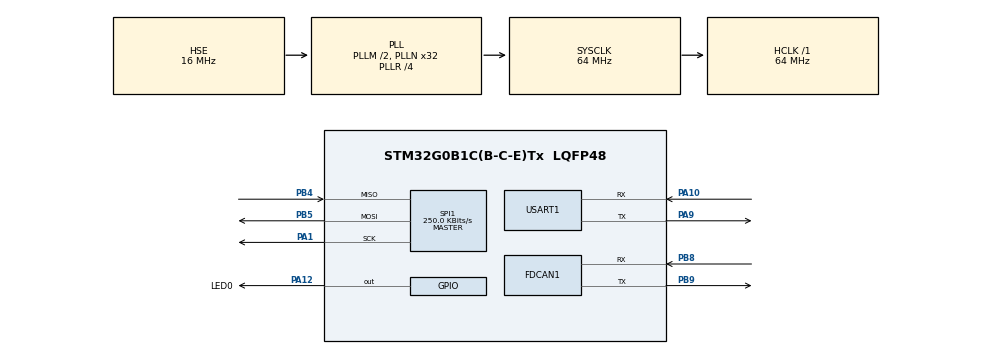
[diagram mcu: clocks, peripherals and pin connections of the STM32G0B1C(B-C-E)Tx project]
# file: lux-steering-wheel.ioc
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FDCAN1.CalculateBaudRateNominal=500000
FDCAN1.CalculateTimeBitNominal=2000
FDCAN1.CalculateTimeQuantumNominal=125.0
FDCAN1.DataPrescaler=8
FDCAN1.DataTimeSeg1=13
FDCAN1.DataTimeSeg2=2
FDCAN1.ExtFiltersNbr=8
FDCAN1.NominalPrescaler=8
FDCAN1.NominalTimeSeg1=12
FDCAN1.NominalTimeSeg2=3
FDCAN1.StdFiltersNbr=28
Mcu.Family=STM32G0
Mcu.Name=STM32G0B1C(B-C-E)Tx
Mcu.Package=LQFP48
NVIC.TIM14_IRQn=true\:0\:0\:false\:false\:true\:true\:true\:true
NVIC.TIM16_FDCAN_IT0_IRQn=true\:0\:0\:false\:false\:true\:true\:true\:true
NVIC.TIM17_FDCAN_IT1_IRQn=true\:0\:0\:false\:false\:true\:true\:true\:true
NVIC.TIM3_TIM4_IRQn=true\:0\:0\:false\:false\:true\:true\:true\:true
NVIC.TIM6_DAC_LPTIM1_IRQn=true\:0\:0\:false\:false\:false\:true\:true\:true
NVIC.TIM7_LPTIM2_IRQn=true\:0\:0\:false\:false\:true\:true\:true\:true
NVIC.USART1_IRQn=true\:0\:0\:false\:false\:true\:true\:true\:true
PA1.Mode=Full_Duplex_Master
PA1.Signal=SPI1_SCK
PA10.Mode=Asynchronous
PA10.Signal=USART1_RX
PA12\ [PA10].GPIO_Label=LED0
PA12\ [PA10].Signal=GPIO_Output
PA13.Mode=Serial_Wire
PA13.Signal=SYS_SWDIO
PA14-BOOT0.Mode=Serial_Wire
PA14-BOOT0.Signal=SYS_SWCLK
PA9.Mode=Asynchronous
PA9.Signal=USART1_TX
PB4.Mode=Full_Duplex_Master
PB4.Signal=SPI1_MISO
PB5.Mode=Full_Duplex_Master
PB5.Signal=SPI1_MOSI
PB8.Mode=FDCAN_Activate
PB8.Signal=FDCAN1_RX
PB9.Mode=FDCAN_Activate
PB9.Signal=FDCAN1_TX
PF0-OSC_IN\ (PF0).Mode=HSE-External-Oscillator
PF0-OSC_IN\ (PF0).Signal=RCC_OSC_IN
PF1-OSC_OUT\ (PF1).Mode=HSE-External-Oscillator
PF1-OSC_OUT\ (PF1).Signal=RCC_OSC_OUT
ProjectManager.HeapSize=0x200
ProjectManager.StackSize=0x400
ProjectManager.TargetToolchain=STM32CubeIDE
RCC.ADCFreq_Value=64000000
RCC.AHBFreq_Value=64000000
RCC.CortexFreq_Value=64000000
RCC.EXTERNAL_CLOCK_VALUE=48000
RCC.HCLKFreq_Value=64000000
RCC.HSE_VALUE=16000000
RCC.HSI48_VALUE=48000000
RCC.HSI_VALUE=16000000
RCC.LSE_VALUE=32768
RCC.PLLM=RCC_PLLM_DIV2
RCC.PLLN=32
RCC.PLLQ=RCC_PLLQ_DIV4
RCC.PLLR=RCC_PLLR_DIV4
RCC.PLLSourceVirtual=RCC_PLLSOURCE_HSE
RCC.SYSCLKFreq_VALUE=64000000
RCC.SYSCLKSource=RCC_SYSCLKSOURCE_PLLCLK
RCC.USBFreq_Value=48000000
RCC.VCOOutputFreq_Value=256000000
SPI1.BaudRatePrescaler=SPI_BAUDRATEPRESCALER_256
SPI1.CalculateBaudRate=250.0 KBits/s
SPI1.DataSize=SPI_DATASIZE_8BIT
SPI1.Direction=SPI_DIRECTION_2LINES
SPI1.Mode=SPI_MODE_MASTER
SPI1.VirtualNSS=VM_NSSHARD
SPI1.VirtualType=VM_MASTER
TIM14.AutoReloadPreload=TIM_AUTORELOAD_PRELOAD_ENABLE
TIM14.Period=(1000/20)-1
TIM14.Prescaler=64000-1
TIM16.AutoReloadPreload=TIM_AUTORELOAD_PRELOAD_ENABLE
TIM16.Period=100-1
TIM16.Prescaler=64000-1
TIM17.AutoReloadPreload=TIM_AUTORELOAD_PRELOAD_ENABLE
TIM17.Period=2000-1
TIM17.Prescaler=64000-1
TIM2.Prescaler=63
TIM4.Prescaler=79
TIM6.AutoReloadPreload=TIM_AUTORELOAD_PRELOAD_ENABLE
TIM6.Period=10-1
TIM6.Prescaler=64000-1
TIM7.AutoReloadPreload=TIM_AUTORELOAD_PRELOAD_ENABLE
TIM7.Period=100-1
TIM7.Prescaler=64000-1
USART1.OverSampling=UART_OVERSAMPLING_16
USART1.VirtualMode-Asynchronous=VM_ASYNC
VP_SYS_VS_DBSignals.Mode=DisableDeadBatterySignals
VP_TIM14_VS_ClockSourceINT.Mode=Enable_Timer
VP_TIM16_VS_ClockSourceINT.Mode=Enable_Timer
VP_TIM17_VS_ClockSourceINT.Mode=Enable_Timer
VP_TIM2_VS_ClockSourceINT.Mode=Internal
VP_TIM4_VS_ClockSourceINT.Mode=Internal
VP_TIM6_VS_ClockSourceINT.Mode=Enable_Timer
VP_TIM7_VS_ClockSourceINT.Mode=Enable_Timer
board=custom

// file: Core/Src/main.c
/* USER CODE BEGIN Header */
/**
  ******************************************************************************
  * @file           : main.c
  * @brief          : Main program body
  ******************************************************************************
  * @attention
  *
  * Copyright (c) 2025 STMicroelectronics.
  * All rights reserved.
  *
  * This software is licensed under terms that can be found in the LICENSE file
  * in the root directory of this software component.
  * If no LICENSE file comes with this software, it is provided AS-IS.
  *
  ******************************************************************************
  */
/* USER CODE END Header */
#include "main.h"

/* USER CODE BEGIN Includes */
#include "run.h"
/* USER CODE END Includes */

FDCAN_HandleTypeDef hfdcan1;

SPI_HandleTypeDef hspi1;

TIM_HandleTypeDef htim2;
TIM_HandleTypeDef htim4;
TIM_HandleTypeDef htim6;
TIM_HandleTypeDef htim7;
TIM_HandleTypeDef htim14;
TIM_HandleTypeDef htim16;
TIM_HandleTypeDef htim17;

UART_HandleTypeDef huart1;

void SystemClock_Config(void);
static void MX_GPIO_Init(void);
static void MX_FDCAN1_Init(void);
static void MX_USART1_UART_Init(void);
static void MX_TIM6_Init(void);
static void MX_TIM7_Init(void);
static void MX_TIM16_Init(void);
static void MX_TIM17_Init(void);
static void MX_TIM14_Init(void);
static void MX_SPI1_Init(void);
static void MX_TIM4_Init(void);
static void MX_TIM2_Init(void);

int main(void)
{

  /* MCU Configuration--------------------------------------------------------*/

  /* Reset of all peripherals, Initializes the Flash interface and the Systick. */
  HAL_Init();

  /* Configure the system clock */
  SystemClock_Config();

  /* Initialize all configured peripherals */
  MX_GPIO_Init();
  MX_FDCAN1_Init();
  MX_USART1_UART_Init();
  MX_TIM6_Init();
  MX_TIM7_Init();
  MX_TIM16_Init();
  MX_TIM17_Init();
  MX_TIM14_Init();
  MX_SPI1_Init();
  MX_TIM4_Init();
  MX_TIM2_Init();
  run();
  /* Infinite loop */
  while (1)
  {

  }
}

void SystemClock_Config(void)
{
  RCC_OscInitTypeDef RCC_OscInitStruct = {0};
  RCC_ClkInitTypeDef RCC_ClkInitStruct = {0};

  /** Configure the main internal regulator output voltage
  */
  HAL_PWREx_ControlVoltageScaling(PWR_REGULATOR_VOLTAGE_SCALE1);

  /** Initializes the RCC Oscillators according to the specified parameters
  * in the RCC_OscInitTypeDef structure.
  */
  RCC_OscInitStruct.OscillatorType = RCC_OSCILLATORTYPE_HSE;
  RCC_OscInitStruct.HSEState = RCC_HSE_ON;
  RCC_OscInitStruct.PLL.PLLState = RCC_PLL_ON;
  RCC_OscInitStruct.PLL.PLLSource = RCC_PLLSOURCE_HSE;
  RCC_OscInitStruct.PLL.PLLM = RCC_PLLM_DIV2;
  RCC_OscInitStruct.PLL.PLLN = 32;
  RCC_OscInitStruct.PLL.PLLP = RCC_PLLP_DIV2;
  RCC_OscInitStruct.PLL.PLLQ = RCC_PLLQ_DIV4;
  RCC_OscInitStruct.PLL.PLLR = RCC_PLLR_DIV4;
  if (HAL_RCC_OscConfig(&RCC_OscInitStruct) != HAL_OK)
  {
    Error_Handler();
  }

  /** Initializes the CPU, AHB and APB buses clocks
  */
  RCC_ClkInitStruct.ClockType = RCC_CLOCKTYPE_HCLK|RCC_CLOCKTYPE_SYSCLK
                              |RCC_CLOCKTYPE_PCLK1;
  RCC_ClkInitStruct.SYSCLKSource = RCC_SYSCLKSOURCE_PLLCLK;
  RCC_ClkInitStruct.AHBCLKDivider = RCC_SYSCLK_DIV1;
  RCC_ClkInitStruct.APB1CLKDivider = RCC_HCLK_DIV1;

  if (HAL_RCC_ClockConfig(&RCC_ClkInitStruct, FLASH_LATENCY_2) != HAL_OK)
  {
    Error_Handler();
  }
}

static void MX_FDCAN1_Init(void)
{

  hfdcan1.Instance = FDCAN1;
  hfdcan1.Init.ClockDivider = FDCAN_CLOCK_DIV1;
  hfdcan1.Init.FrameFormat = FDCAN_FRAME_CLASSIC;
  hfdcan1.Init.Mode = FDCAN_MODE_NORMAL;
  hfdcan1.Init.AutoRetransmission = DISABLE;
  hfdcan1.Init.TransmitPause = DISABLE;
  hfdcan1.Init.ProtocolException = DISABLE;
  hfdcan1.Init.NominalPrescaler = 8;
  hfdcan1.Init.NominalSyncJumpWidth = 1;
  hfdcan1.Init.NominalTimeSeg1 = 12;
  hfdcan1.Init.NominalTimeSeg2 = 3;
  hfdcan1.Init.DataPrescaler = 8;
  hfdcan1.Init.DataSyncJumpWidth = 1;
  hfdcan1.Init.DataTimeSeg1 = 13;
  hfdcan1.Init.DataTimeSeg2 = 2;
  hfdcan1.Init.StdFiltersNbr = 28;
  hfdcan1.Init.ExtFiltersNbr = 8;
  hfdcan1.Init.TxFifoQueueMode = FDCAN_TX_FIFO_OPERATION;
  if (HAL_FDCAN_Init(&hfdcan1) != HAL_OK)
  {
    Error_Handler();
  }

}

static void MX_SPI1_Init(void)
{

  /* SPI1 parameter configuration*/
  hspi1.Instance = SPI1;
  hspi1.Init.Mode = SPI_MODE_MASTER;
  hspi1.Init.Direction = SPI_DIRECTION_2LINES;
  hspi1.Init.DataSize = SPI_DATASIZE_8BIT;
  hspi1.Init.CLKPolarity = SPI_POLARITY_LOW;
  hspi1.Init.CLKPhase = SPI_PHASE_1EDGE;
  hspi1.Init.NSS = SPI_NSS_SOFT;
  hspi1.Init.BaudRatePrescaler = SPI_BAUDRATEPRESCALER_256;
  hspi1.Init.FirstBit = SPI_FIRSTBIT_MSB;
  hspi1.Init.TIMode = SPI_TIMODE_DISABLE;
  hspi1.Init.CRCCalculation = SPI_CRCCALCULATION_DISABLE;
  hspi1.Init.CRCPolynomial = 7;
  hspi1.Init.CRCLength = SPI_CRC_LENGTH_DATASIZE;
  hspi1.Init.NSSPMode = SPI_NSS_PULSE_ENABLE;
  if (HAL_SPI_Init(&hspi1) != HAL_OK)
  {
    Error_Handler();
  }

}

static void MX_TIM2_Init(void)
{

  TIM_ClockConfigTypeDef sClockSourceConfig = {0};
  TIM_MasterConfigTypeDef sMasterConfig = {0};

  htim2.Instance = TIM2;
  htim2.Init.Prescaler = 63;
  htim2.Init.CounterMode = TIM_COUNTERMODE_UP;
  htim2.Init.Period = 4294967295;
  htim2.Init.ClockDivision = TIM_CLOCKDIVISION_DIV1;
  htim2.Init.AutoReloadPreload = TIM_AUTORELOAD_PRELOAD_DISABLE;
  if (HAL_TIM_Base_Init(&htim2) != HAL_OK)
  {
    Error_Handler();
  }
  sClockSourceConfig.ClockSource = TIM_CLOCKSOURCE_INTERNAL;
  if (HAL_TIM_ConfigClockSource(&htim2, &sClockSourceConfig) != HAL_OK)
  {
    Error_Handler();
  }
  sMasterConfig.MasterOutputTrigger = TIM_TRGO_RESET;
  sMasterConfig.MasterSlaveMode = TIM_MASTERSLAVEMODE_DISABLE;
  if (HAL_TIMEx_MasterConfigSynchronization(&htim2, &sMasterConfig) != HAL_OK)
  {
    Error_Handler();
  }

}

static void MX_TIM4_Init(void)
{

  TIM_ClockConfigTypeDef sClockSourceConfig = {0};
  TIM_MasterConfigTypeDef sMasterConfig = {0};

  htim4.Instance = TIM4;
  htim4.Init.Prescaler = 79;
  htim4.Init.CounterMode = TIM_COUNTERMODE_UP;
  htim4.Init.Period = 65535;
  htim4.Init.ClockDivision = TIM_CLOCKDIVISION_DIV1;
  htim4.Init.AutoReloadPreload = TIM_AUTORELOAD_PRELOAD_DISABLE;
  if (HAL_TIM_Base_Init(&htim4) != HAL_OK)
  {
    Error_Handler();
  }
  sClockSourceConfig.ClockSource = TIM_CLOCKSOURCE_INTERNAL;
  if (HAL_TIM_ConfigClockSource(&htim4, &sClockSourceConfig) != HAL_OK)
  {
    Error_Handler();
  }
  sMasterConfig.MasterOutputTrigger = TIM_TRGO_RESET;
  sMasterConfig.MasterSlaveMode = TIM_MASTERSLAVEMODE_DISABLE;
  if (HAL_TIMEx_MasterConfigSynchronization(&htim4, &sMasterConfig) != HAL_OK)
  {
    Error_Handler();
  }

}

static void MX_TIM6_Init(void)
{

  TIM_MasterConfigTypeDef sMasterConfig = {0};

  htim6.Instance = TIM6;
  htim6.Init.Prescaler = 64000-1;
  htim6.Init.CounterMode = TIM_COUNTERMODE_UP;
  htim6.Init.Period = 10-1;
  htim6.Init.AutoReloadPreload = TIM_AUTORELOAD_PRELOAD_ENABLE;
  if (HAL_TIM_Base_Init(&htim6) != HAL_OK)
  {
    Error_Handler();
  }
  sMasterConfig.MasterOutputTrigger = TIM_TRGO_RESET;
  sMasterConfig.MasterSlaveMode = TIM_MASTERSLAVEMODE_DISABLE;
  if (HAL_TIMEx_MasterConfigSynchronization(&htim6, &sMasterConfig) != HAL_OK)
  {
    Error_Handler();
  }

}

static void MX_TIM7_Init(void)
{

  TIM_MasterConfigTypeDef sMasterConfig = {0};

  htim7.Instance = TIM7;
  htim7.Init.Prescaler = 64000-1;
  htim7.Init.CounterMode = TIM_COUNTERMODE_UP;
  htim7.Init.Period = 100-1;
  htim7.Init.AutoReloadPreload = TIM_AUTORELOAD_PRELOAD_ENABLE;
  if (HAL_TIM_Base_Init(&htim7) != HAL_OK)
  {
    Error_Handler();
  }
  sMasterConfig.MasterOutputTrigger = TIM_TRGO_RESET;
  sMasterConfig.MasterSlaveMode = TIM_MASTERSLAVEMODE_DISABLE;
  if (HAL_TIMEx_MasterConfigSynchronization(&htim7, &sMasterConfig) != HAL_OK)
  {
    Error_Handler();
  }

}

static void MX_TIM14_Init(void)
{

  htim14.Instance = TIM14;
  htim14.Init.Prescaler = 64000-1;
  htim14.Init.CounterMode = TIM_COUNTERMODE_UP;
  htim14.Init.Period = (1000/20)-1;
  htim14.Init.ClockDivision = TIM_CLOCKDIVISION_DIV1;
  htim14.Init.AutoReloadPreload = TIM_AUTORELOAD_PRELOAD_ENABLE;
  if (HAL_TIM_Base_Init(&htim14) != HAL_OK)
  {
    Error_Handler();
  }

}

static void MX_TIM16_Init(void)
{

  htim16.Instance = TIM16;
  htim16.Init.Prescaler = 64000-1;
  htim16.Init.CounterMode = TIM_COUNTERMODE_UP;
  htim16.Init.Period = 100-1;
  htim16.Init.ClockDivision = TIM_CLOCKDIVISION_DIV1;
  htim16.Init.RepetitionCounter = 0;
  htim16.Init.AutoReloadPreload = TIM_AUTORELOAD_PRELOAD_ENABLE;
  if (HAL_TIM_Base_Init(&htim16) != HAL_OK)
  {
    Error_Handler();
  }

}

static void MX_TIM17_Init(void)
{

  htim17.Instance = TIM17;
  htim17.Init.Prescaler = 64000-1;
  htim17.Init.CounterMode = TIM_COUNTERMODE_UP;
  htim17.Init.Period = 2000-1;
  htim17.Init.ClockDivision = TIM_CLOCKDIVISION_DIV1;
  htim17.Init.RepetitionCounter = 0;
  htim17.Init.AutoReloadPreload = TIM_AUTORELOAD_PRELOAD_ENABLE;
  if (HAL_TIM_Base_Init(&htim17) != HAL_OK)
  {
    Error_Handler();
  }

}

static void MX_USART1_UART_Init(void)
{

  huart1.Instance = USART1;
  huart1.Init.BaudRate = 115200;
  huart1.Init.WordLength = UART_WORDLENGTH_8B;
  huart1.Init.StopBits = UART_STOPBITS_1;
  huart1.Init.Parity = UART_PARITY_NONE;
  huart1.Init.Mode = UART_MODE_TX_RX;
  huart1.Init.HwFlowCtl = UART_HWCONTROL_NONE;
  huart1.Init.OverSampling = UART_OVERSAMPLING_16;
  huart1.Init.OneBitSampling = UART_ONE_BIT_SAMPLE_DISABLE;
  huart1.Init.ClockPrescaler = UART_PRESCALER_DIV1;
  huart1.AdvancedInit.AdvFeatureInit = UART_ADVFEATURE_NO_INIT;
  if (HAL_UART_Init(&huart1) != HAL_OK)
  {
    Error_Handler();
  }
  if (HAL_UARTEx_SetTxFifoThreshold(&huart1, UART_TXFIFO_THRESHOLD_1_8) != HAL_OK)
  {
    Error_Handler();
  }
  if (HAL_UARTEx_SetRxFifoThreshold(&huart1, UART_RXFIFO_THRESHOLD_1_8) != HAL_OK)
  {
    Error_Handler();
  }
  if (HAL_UARTEx_DisableFifoMode(&huart1) != HAL_OK)
  {
    Error_Handler();
  }

}

static void MX_GPIO_Init(void)
{
  GPIO_InitTypeDef GPIO_InitStruct = {0};

  /* GPIO Ports Clock Enable */
  __HAL_RCC_GPIOF_CLK_ENABLE();
  __HAL_RCC_GPIOA_CLK_ENABLE();
  __HAL_RCC_GPIOB_CLK_ENABLE();

  /*Configure GPIO pin Output Level */
  HAL_GPIO_WritePin(LED0_GPIO_Port, LED0_Pin, GPIO_PIN_RESET);

  /*Configure GPIO pin : LED0_Pin */
  GPIO_InitStruct.Pin = LED0_Pin;
  GPIO_InitStruct.Mode = GPIO_MODE_OUTPUT_PP;
  GPIO_InitStruct.Pull = GPIO_NOPULL;
  GPIO_InitStruct.Speed = GPIO_SPEED_FREQ_LOW;
  HAL_GPIO_Init(LED0_GPIO_Port, &GPIO_InitStruct);

}

void Error_Handler(void)
{
  __disable_irq();
  while (1)
  {
  }
}
